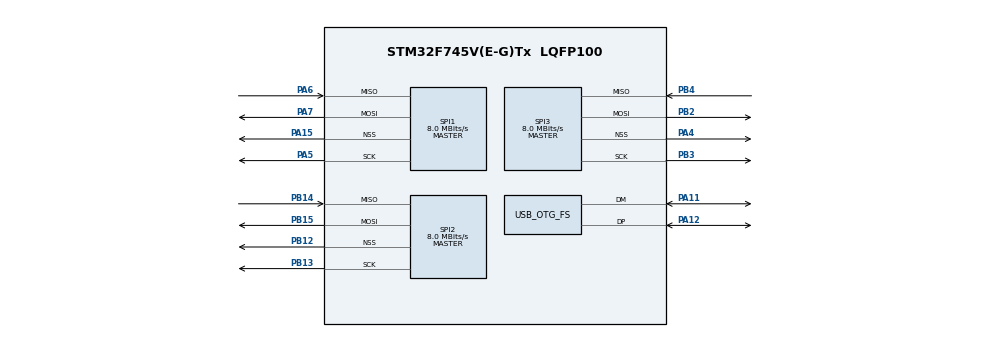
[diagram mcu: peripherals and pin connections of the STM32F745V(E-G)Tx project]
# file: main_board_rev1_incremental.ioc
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FREERTOS.Tasks01=defaultTask,24,512,StartDefaultTask,Default,NULL,Dynamic,NULL,NULL;taskSensRead,24,2048,vTaskSensRead,Default,NULL,Static,taskSensReadBuffer,taskSensReadControlBlock
Mcu.Family=STM32F7
Mcu.Name=STM32F745V(E-G)Tx
Mcu.Package=LQFP100
NVIC.OTG_FS_IRQn=true\:5\:0\:false\:false\:true\:true\:false\:true
NVIC.PriorityGroup=NVIC_PRIORITYGROUP_4
NVIC.TIM1_UP_TIM10_IRQn=true\:0\:0\:false\:false\:true\:false\:false\:true
NVIC.TimeBase=TIM1_UP_TIM10_IRQn
NVIC.TimeBaseIP=TIM1
PA11.Mode=Device_Only
PA11.Signal=USB_OTG_FS_DM
PA12.Mode=Device_Only
PA12.Signal=USB_OTG_FS_DP
PA13.Mode=Serial_Wire
PA13.Signal=SYS_JTMS-SWDIO
PA14.Mode=Serial_Wire
PA14.Signal=SYS_JTCK-SWCLK
PA15.Mode=NSS_Signal_Hard_Output
PA15.Signal=SPI1_NSS
PA4.Mode=NSS_Signal_Hard_Output
PA4.Signal=SPI3_NSS
PA5.Mode=Full_Duplex_Master
PA5.Signal=SPI1_SCK
PA6.Mode=Full_Duplex_Master
PA6.Signal=SPI1_MISO
PA7.Mode=Full_Duplex_Master
PA7.Signal=SPI1_MOSI
PB12.Mode=NSS_Signal_Hard_Output
PB12.Signal=SPI2_NSS
PB13.Mode=Full_Duplex_Master
PB13.Signal=SPI2_SCK
PB14.Mode=Full_Duplex_Master
PB14.Signal=SPI2_MISO
PB15.Mode=Full_Duplex_Master
PB15.Signal=SPI2_MOSI
PB2.Mode=Full_Duplex_Master
PB2.Signal=SPI3_MOSI
PB3.Mode=Full_Duplex_Master
PB3.Signal=SPI3_SCK
PB4.Mode=Full_Duplex_Master
PB4.Signal=SPI3_MISO
PH0/OSC_IN.Mode=HSE-External-Oscillator
PH0/OSC_IN.Signal=RCC_OSC_IN
PH1/OSC_OUT.Mode=HSE-External-Oscillator
PH1/OSC_OUT.Signal=RCC_OSC_OUT
ProjectManager.HeapSize=0x200
ProjectManager.StackSize=0x400
ProjectManager.TargetToolchain=STM32CubeIDE
RCC.HSE_VALUE=25000000
RCC.HSI_VALUE=16000000
RCC.LSE_VALUE=32768
RCC.PLLM=15
RCC.PLLN=144
RCC.PLLQ=5
RCC.USBFreq_Value=48000000
RCC.VCOOutputFreq_Value=240000000
SPI1.CalculateBaudRate=8.0 MBits/s
SPI1.Direction=SPI_DIRECTION_2LINES
SPI1.Mode=SPI_MODE_MASTER
SPI1.VirtualNSS=VM_NSSHARD
SPI1.VirtualType=VM_MASTER
SPI2.CalculateBaudRate=8.0 MBits/s
SPI2.Direction=SPI_DIRECTION_2LINES
SPI2.Mode=SPI_MODE_MASTER
SPI2.VirtualNSS=VM_NSSHARD
SPI2.VirtualType=VM_MASTER
SPI3.CalculateBaudRate=8.0 MBits/s
SPI3.Direction=SPI_DIRECTION_2LINES
SPI3.Mode=SPI_MODE_MASTER
SPI3.VirtualNSS=VM_NSSHARD
SPI3.VirtualType=VM_MASTER
USB_DEVICE.CLASS_NAME_FS=CDC
USB_DEVICE.VirtualMode-CDC_FS=Cdc
USB_DEVICE.VirtualModeFS=Cdc_FS
USB_OTG_FS.VirtualMode=Device_Only
VP_FREERTOS_VS_CMSIS_V2.Mode=CMSIS_V2
VP_SYS_VS_tim1.Mode=TIM1
VP_USB_DEVICE_VS_USB_DEVICE_CDC_FS.Mode=CDC_FS
board=custom

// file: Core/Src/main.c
/* USER CODE BEGIN Header */
/**
  ******************************************************************************
  * @file           : main.c
  * @brief          : Main program body
  ******************************************************************************
  * @attention
  *
  * <h2><center>&copy; Copyright (c) 2019 STMicroelectronics.
  * All rights reserved.</center></h2>
  *
  * This software component is licensed by ST under BSD 3-Clause license,
  * the "License"; You may not use this file except in compliance with the
  * License. You may obtain a copy of the License at:
  *                        opensource.org/licenses/BSD-3-Clause
  *
  ******************************************************************************
  */
/* USER CODE END Header */

#include "main.h"
#include "cmsis_os.h"
#include "usb_device.h"

SPI_HandleTypeDef hspi1;
SPI_HandleTypeDef hspi2;
SPI_HandleTypeDef hspi3;

typedef StaticTask_t osStaticThreadDef_t;
osThreadId_t defaultTaskHandle;
osThreadId_t taskSensReadHandle;
uint32_t taskSensReadBuffer[ 2048 ];
osStaticThreadDef_t taskSensReadControlBlock;

void SystemClock_Config(void);
static void MX_GPIO_Init(void);
static void MX_SPI1_Init(void);
static void MX_SPI2_Init(void);
static void MX_SPI3_Init(void);
void StartDefaultTask(void *argument);
void vTaskSensRead(void *argument);

int main(void)
{

  /* MCU Configuration--------------------------------------------------------*/

  /* Reset of all peripherals, Initializes the Flash interface and the Systick. */
  HAL_Init();
  //HAL_Delay(1000);
  /* USER CODE BEGIN Init */
  //This is needed in order for line-by-line debugging to work
  //https://community.st.com/s/question/0D50X00009XkgyISAR/stm32f7-debugging-stepping-impossible-ide-jumps-into-interrupts
  (DBGMCU)->APB1FZ = 0x7E01BFF;
  (DBGMCU)->APB2FZ = 0x70003;

  /* USER CODE END Init */

  /* Configure the system clock */
  SystemClock_Config();

  /* Initialize all configured peripherals */
  MX_GPIO_Init();
  MX_SPI1_Init();
  MX_SPI2_Init();
  MX_SPI3_Init();
  //HAL_Delay(1000);
  //MX_USB_DEVICE_Init();
  //HAL_Delay(1000);

  osKernelInitialize();

  /* Create the thread(s) */
  /* definition and creation of defaultTask */
  const osThreadAttr_t defaultTask_attributes = {
    .name = "defaultTask",
    .priority = (osPriority_t) osPriorityNormal,
    .stack_size = 512
  };
  defaultTaskHandle = osThreadNew(StartDefaultTask, NULL, &defaultTask_attributes);

  /* definition and creation of taskSensRead */
  const osThreadAttr_t taskSensRead_attributes = {
    .name = "taskSensRead",
    .stack_mem = &taskSensReadBuffer[0],
    .stack_size = sizeof(taskSensReadBuffer),
    .cb_mem = &taskSensReadControlBlock,
    .cb_size = sizeof(taskSensReadControlBlock),
    .priority = (osPriority_t) osPriorityNormal,
  };
  taskSensReadHandle = osThreadNew(vTaskSensRead, NULL, &taskSensRead_attributes);

  /* Start scheduler */
  osKernelStart();

  /* We should never get here as control is now taken by the scheduler */

  /* Infinite loop */
  while (1)
  {

  }
}

void SystemClock_Config(void)
{
  RCC_OscInitTypeDef RCC_OscInitStruct = {0};
  RCC_ClkInitTypeDef RCC_ClkInitStruct = {0};
  RCC_PeriphCLKInitTypeDef PeriphClkInitStruct = {0};

  /** Configure the main internal regulator output voltage
  */
  __HAL_RCC_PWR_CLK_ENABLE();
  __HAL_PWR_VOLTAGESCALING_CONFIG(PWR_REGULATOR_VOLTAGE_SCALE3);
  /** Initializes the CPU, AHB and APB busses clocks
  */
  RCC_OscInitStruct.OscillatorType = RCC_OSCILLATORTYPE_HSI|RCC_OSCILLATORTYPE_HSE;
  RCC_OscInitStruct.HSEState = RCC_HSE_ON;
  RCC_OscInitStruct.HSIState = RCC_HSI_ON;
  RCC_OscInitStruct.HSICalibrationValue = RCC_HSICALIBRATION_DEFAULT;
  RCC_OscInitStruct.PLL.PLLState = RCC_PLL_ON;
  RCC_OscInitStruct.PLL.PLLSource = RCC_PLLSOURCE_HSE;
  RCC_OscInitStruct.PLL.PLLM = 15;
  RCC_OscInitStruct.PLL.PLLN = 144;
  RCC_OscInitStruct.PLL.PLLP = RCC_PLLP_DIV2;
  RCC_OscInitStruct.PLL.PLLQ = 5;
  if (HAL_RCC_OscConfig(&RCC_OscInitStruct) != HAL_OK)
  {
    Error_Handler();
  }
  /** Initializes the CPU, AHB and APB busses clocks
  */
  RCC_ClkInitStruct.ClockType = RCC_CLOCKTYPE_HCLK|RCC_CLOCKTYPE_SYSCLK
                              |RCC_CLOCKTYPE_PCLK1|RCC_CLOCKTYPE_PCLK2;
  RCC_ClkInitStruct.SYSCLKSource = RCC_SYSCLKSOURCE_HSI;
  RCC_ClkInitStruct.AHBCLKDivider = RCC_SYSCLK_DIV1;
  RCC_ClkInitStruct.APB1CLKDivider = RCC_HCLK_DIV1;
  RCC_ClkInitStruct.APB2CLKDivider = RCC_HCLK_DIV1;

  if (HAL_RCC_ClockConfig(&RCC_ClkInitStruct, FLASH_LATENCY_0) != HAL_OK)
  {
    Error_Handler();
  }
  PeriphClkInitStruct.PeriphClockSelection = RCC_PERIPHCLK_CLK48;
  PeriphClkInitStruct.Clk48ClockSelection = RCC_CLK48SOURCE_PLL;
  if (HAL_RCCEx_PeriphCLKConfig(&PeriphClkInitStruct) != HAL_OK)
  {
    Error_Handler();
  }
}

static void MX_SPI1_Init(void)
{

  /* SPI1 parameter configuration*/
  hspi1.Instance = SPI1;
  hspi1.Init.Mode = SPI_MODE_MASTER;
  hspi1.Init.Direction = SPI_DIRECTION_2LINES;
  hspi1.Init.DataSize = SPI_DATASIZE_4BIT;
  hspi1.Init.CLKPolarity = SPI_POLARITY_LOW;
  hspi1.Init.CLKPhase = SPI_PHASE_1EDGE;
  hspi1.Init.NSS = SPI_NSS_HARD_OUTPUT;
  hspi1.Init.BaudRatePrescaler = SPI_BAUDRATEPRESCALER_2;
  hspi1.Init.FirstBit = SPI_FIRSTBIT_MSB;
  hspi1.Init.TIMode = SPI_TIMODE_DISABLE;
  hspi1.Init.CRCCalculation = SPI_CRCCALCULATION_DISABLE;
  hspi1.Init.CRCPolynomial = 7;
  hspi1.Init.CRCLength = SPI_CRC_LENGTH_DATASIZE;
  hspi1.Init.NSSPMode = SPI_NSS_PULSE_ENABLE;
  if (HAL_SPI_Init(&hspi1) != HAL_OK)
  {
    Error_Handler();
  }

}

static void MX_SPI2_Init(void)
{

  /* SPI2 parameter configuration*/
  hspi2.Instance = SPI2;
  hspi2.Init.Mode = SPI_MODE_MASTER;
  hspi2.Init.Direction = SPI_DIRECTION_2LINES;
  hspi2.Init.DataSize = SPI_DATASIZE_4BIT;
  hspi2.Init.CLKPolarity = SPI_POLARITY_LOW;
  hspi2.Init.CLKPhase = SPI_PHASE_1EDGE;
  hspi2.Init.NSS = SPI_NSS_HARD_OUTPUT;
  hspi2.Init.BaudRatePrescaler = SPI_BAUDRATEPRESCALER_2;
  hspi2.Init.FirstBit = SPI_FIRSTBIT_MSB;
  hspi2.Init.TIMode = SPI_TIMODE_DISABLE;
  hspi2.Init.CRCCalculation = SPI_CRCCALCULATION_DISABLE;
  hspi2.Init.CRCPolynomial = 7;
  hspi2.Init.CRCLength = SPI_CRC_LENGTH_DATASIZE;
  hspi2.Init.NSSPMode = SPI_NSS_PULSE_ENABLE;
  if (HAL_SPI_Init(&hspi2) != HAL_OK)
  {
    Error_Handler();
  }

}

static void MX_SPI3_Init(void)
{

  /* SPI3 parameter configuration*/
  hspi3.Instance = SPI3;
  hspi3.Init.Mode = SPI_MODE_MASTER;
  hspi3.Init.Direction = SPI_DIRECTION_2LINES;
  hspi3.Init.DataSize = SPI_DATASIZE_4BIT;
  hspi3.Init.CLKPolarity = SPI_POLARITY_LOW;
  hspi3.Init.CLKPhase = SPI_PHASE_1EDGE;
  hspi3.Init.NSS = SPI_NSS_HARD_OUTPUT;
  hspi3.Init.BaudRatePrescaler = SPI_BAUDRATEPRESCALER_2;
  hspi3.Init.FirstBit = SPI_FIRSTBIT_MSB;
  hspi3.Init.TIMode = SPI_TIMODE_DISABLE;
  hspi3.Init.CRCCalculation = SPI_CRCCALCULATION_DISABLE;
  hspi3.Init.CRCPolynomial = 7;
  hspi3.Init.CRCLength = SPI_CRC_LENGTH_DATASIZE;
  hspi3.Init.NSSPMode = SPI_NSS_PULSE_ENABLE;
  if (HAL_SPI_Init(&hspi3) != HAL_OK)
  {
    Error_Handler();
  }

}

static void MX_GPIO_Init(void)
{

  /* GPIO Ports Clock Enable */
  __HAL_RCC_GPIOH_CLK_ENABLE();
  __HAL_RCC_GPIOA_CLK_ENABLE();
  __HAL_RCC_GPIOB_CLK_ENABLE();

}

void StartDefaultTask(void *argument)
{
  /* init code for USB_DEVICE */
  //MX_USB_DEVICE_Init();
  for(;;)
  {
    osDelay(1);
  }
}

void HAL_TIM_PeriodElapsedCallback(TIM_HandleTypeDef *htim)
{
  if (htim->Instance == TIM1) {
    HAL_IncTick();
  }
}

void Error_Handler(void)
{
}

/************************ (C) COPYRIGHT STMicroelectronics *****END OF FILE****/
